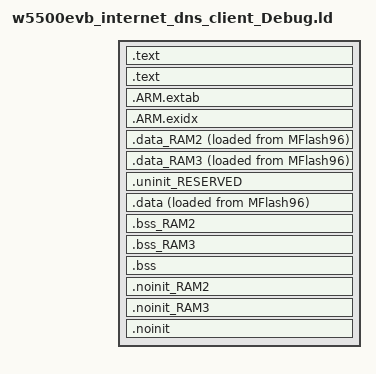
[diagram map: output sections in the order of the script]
/*
 * GENERATED FILE - DO NOT EDIT
 * (c) Code Red Technologies Ltd, 2008-${year}
 * (c) NXP Semiconductors 2013-${year}
 * Generated linker script file for 2014
 * Created from LPC11E36/501 (Tue May 27 10:19:59 KST 2014)
 * By generic_c.ld on LPCXpresso v7.0.0 [Build 92] [2014-02-20] 
 */


INCLUDE "w5500evb_internet_dns_client_Debug_lib.ld"
INCLUDE "w5500evb_internet_dns_client_Debug_mem.ld"

ENTRY(ResetISR)

SECTIONS
{

    /* MAIN TEXT SECTION */    
    .text : ALIGN(4)
    {
        FILL(0xff)
        __vectors_start__ = ABSOLUTE(.) ;
        KEEP(*(.isr_vector))
        
        /* Global Section Table */
        . = ALIGN(4) ;
        __section_table_start = .;
        __data_section_table = .;
        LONG(LOADADDR(.data));
        LONG(    ADDR(.data));
        LONG(  SIZEOF(.data));
        LONG(LOADADDR(.data_RAM2));
        LONG(    ADDR(.data_RAM2));
        LONG(  SIZEOF(.data_RAM2));
        LONG(LOADADDR(.data_RAM3));
        LONG(    ADDR(.data_RAM3));
        LONG(  SIZEOF(.data_RAM3));
        __data_section_table_end = .;
        __bss_section_table = .;
        LONG(    ADDR(.bss));
        LONG(  SIZEOF(.bss));
        LONG(    ADDR(.bss_RAM2));
        LONG(  SIZEOF(.bss_RAM2));
        LONG(    ADDR(.bss_RAM3));
        LONG(  SIZEOF(.bss_RAM3));
        __bss_section_table_end = .;
        __section_table_end = . ;
        /* End of Global Section Table */
        

        *(.after_vectors*)
        
        /* Code Read Protect data */
        . = 0x000002FC ;
        PROVIDE(__CRP_WORD_START__ = .) ;
        KEEP(*(.crp))
        PROVIDE(__CRP_WORD_END__ = .) ;
        ASSERT(!(__CRP_WORD_START__ == __CRP_WORD_END__), "Linker CRP Enabled, but no CRP_WORD provided within application");
        /* End of Code Read Protect */
        
    } >MFlash96
    
    .text : ALIGN(4)    
    {
         *(.text*)
        *(.rodata .rodata.* .constdata .constdata.*)
        . = ALIGN(4);
        
    } > MFlash96

    /*
     * for exception handling/unwind - some Newlib functions (in common
     * with C++ and STDC++) use this. 
     */
    .ARM.extab : ALIGN(4)
    {
    	*(.ARM.extab* .gnu.linkonce.armextab.*)
    } > MFlash96
    __exidx_start = .;
    
    .ARM.exidx : ALIGN(4)
    {
    	*(.ARM.exidx* .gnu.linkonce.armexidx.*)
    } > MFlash96
    __exidx_end = .;
    
    _etext = .;
        
    
    /* DATA section for RamPeriph2 */
    .data_RAM2 : ALIGN(4)
    {
       FILL(0xff)
    	*(.data.$RAM2*)
    	*(.data.$RamPeriph2*)
       . = ALIGN(4) ;
    } > RamPeriph2 AT>MFlash96
    
    /* DATA section for SRAM1_2 */
    .data_RAM3 : ALIGN(4)
    {
       FILL(0xff)
    	*(.data.$RAM3*)
    	*(.data.$SRAM1_2*)
       . = ALIGN(4) ;
    } > SRAM1_2 AT>MFlash96
    
    /* MAIN DATA SECTION */
    

    .uninit_RESERVED : ALIGN(4)
    {
        KEEP(*(.bss.$RESERVED*))
        . = ALIGN(4) ;
        _end_uninit_RESERVED = .;
    } > RamLoc8

	
	/* Main DATA section (RamLoc8) */
	.data : ALIGN(4)
	{
	   FILL(0xff)
	   _data = . ;
	   *(vtable)
	   *(.data*)
	   . = ALIGN(4) ;
	   _edata = . ;
	} > RamLoc8 AT>MFlash96

    /* BSS section for RamPeriph2 */
    .bss_RAM2 : ALIGN(4)
    {
    	*(.bss.$RAM2*)
    	*(.bss.$RamPeriph2*)
       . = ALIGN(4) ;
    } > RamPeriph2
    /* BSS section for SRAM1_2 */
    .bss_RAM3 : ALIGN(4)
    {
    	*(.bss.$RAM3*)
    	*(.bss.$SRAM1_2*)
       . = ALIGN(4) ;
    } > SRAM1_2

    /* MAIN BSS SECTION */
    .bss : ALIGN(4)
    {
        _bss = .;
        *(.bss*)
        *(COMMON)
        . = ALIGN(4) ;
        _ebss = .;
        PROVIDE(end = .);
    } > RamLoc8
        
    /* NOINIT section for RamPeriph2 */
    .noinit_RAM2 (NOLOAD) : ALIGN(4)
    {
    	*(.noinit.$RAM2*)
    	*(.noinit.$RamPeriph2*)
       . = ALIGN(4) ;
    } > RamPeriph2 
    /* NOINIT section for SRAM1_2 */
    .noinit_RAM3 (NOLOAD) : ALIGN(4)
    {
    	*(.noinit.$RAM3*)
    	*(.noinit.$SRAM1_2*)
       . = ALIGN(4) ;
    } > SRAM1_2 
    
    /* DEFAULT NOINIT SECTION */
    .noinit (NOLOAD): ALIGN(4)
    {
        _noinit = .;
        *(.noinit*) 
         . = ALIGN(4) ;
        _end_noinit = .;
    } > RamLoc8
    
    PROVIDE(_pvHeapStart = .);
    PROVIDE(_vStackTop = __top_RamLoc8 - 0);
}
